# PIC32MZ2048EFM144 register map
Registers are 32-bit, access not given, reset 0x0 unless marked. A register's access mark holds for its fields unless they carry their own. Offsets are from the block's base; [hi:lo] are bit positions; {n}, {i} and the like mark numbered series; 'fields as' and 'values as' point back to an identical list.

## CAN2 — CAN2 peripheral
Base 0xBF881000
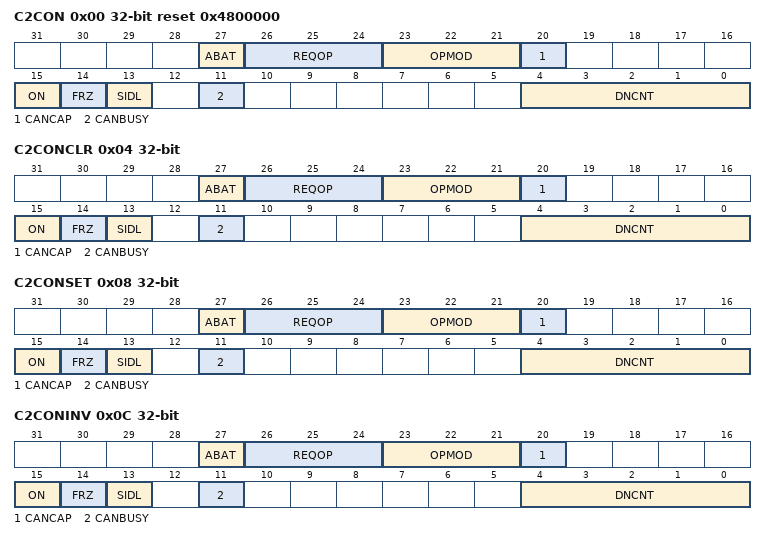
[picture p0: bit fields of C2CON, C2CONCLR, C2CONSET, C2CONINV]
0x00 C2CON reset 0x4800000
  [27] ABAT, [26:24] REQOP, [23:21] OPMOD, [20] CANCAP, [15] ON, [14] FRZ, [13] SIDL, [11] CANBUSY, [4:0] DNCNT
0x04 C2CONCLR
  fields as C2CON
0x08 C2CONSET
  fields as C2CON
0x0C C2CONINV
  fields as C2CON
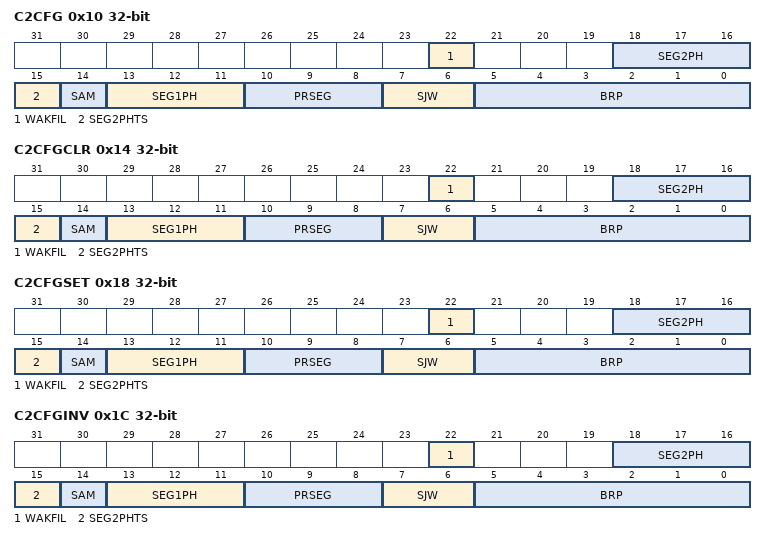
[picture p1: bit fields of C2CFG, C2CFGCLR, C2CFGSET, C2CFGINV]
0x10 C2CFG
  [22] WAKFIL, [18:16] SEG2PH, [15] SEG2PHTS, [14] SAM, [13:11] SEG1PH, [10:8] PRSEG, [7:6] SJW, [5:0] BRP
0x14 C2CFGCLR
  fields as C2CFG
0x18 C2CFGSET
  fields as C2CFG
0x1C C2CFGINV
  fields as C2CFG
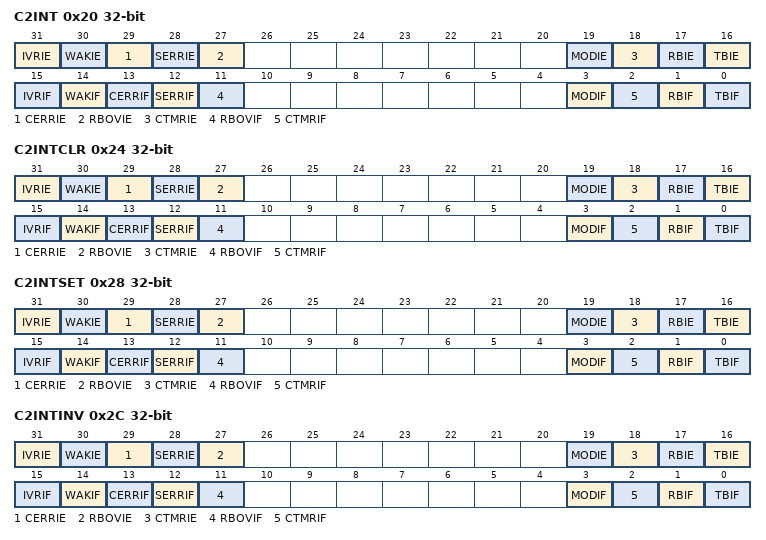
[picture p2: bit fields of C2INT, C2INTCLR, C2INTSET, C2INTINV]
0x20 C2INT
  [31] IVRIE, [30] WAKIE, [29] CERRIE, [28] SERRIE, [27] RBOVIE, [19] MODIE, [18] CTMRIE, [17] RBIE, [16] TBIE, [15] IVRIF, [14] WAKIF, [13] CERRIF, [12] SERRIF, [11] RBOVIF, [3] MODIF, [2] CTMRIF, [1] RBIF, [0] TBIF
0x24 C2INTCLR
  fields as C2INT
0x28 C2INTSET
  fields as C2INT
0x2C C2INTINV
  fields as C2INT
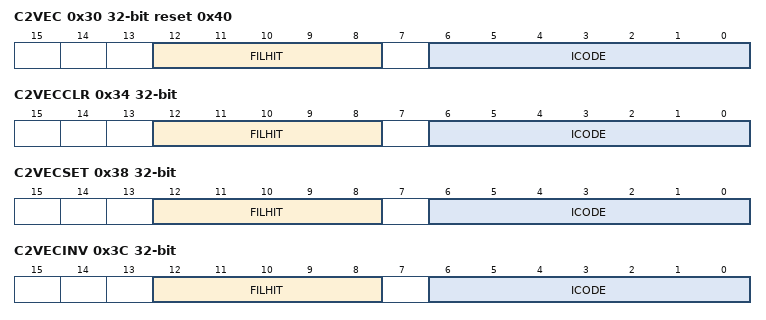
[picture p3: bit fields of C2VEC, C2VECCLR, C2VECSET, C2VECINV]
0x30 C2VEC reset 0x40
  [12:8] FILHIT, [6:0] ICODE
0x34 C2VECCLR
  [12:8] FILHIT, [6:0] ICODE
0x38 C2VECSET
  [12:8] FILHIT, [6:0] ICODE
0x3C C2VECINV
  [12:8] FILHIT, [6:0] ICODE
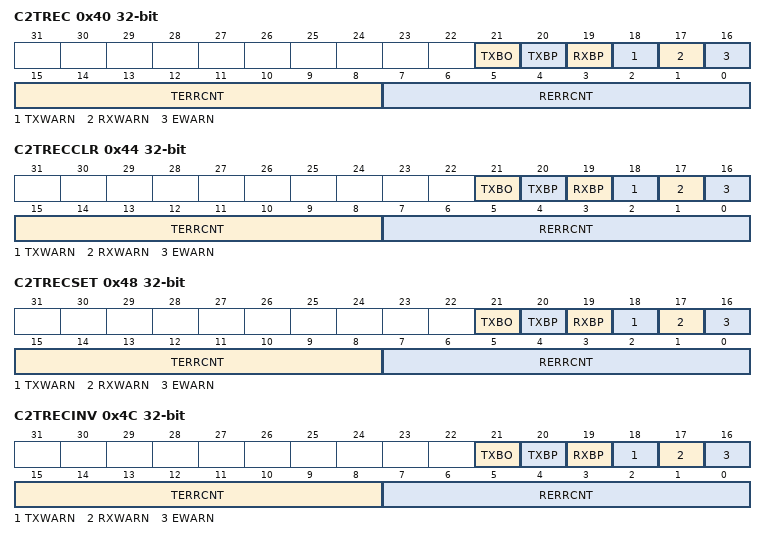
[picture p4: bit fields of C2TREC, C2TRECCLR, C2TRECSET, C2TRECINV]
0x40 C2TREC
  [21] TXBO, [20] TXBP, [19] RXBP, [18] TXWARN, [17] RXWARN, [16] EWARN, [15:8] TERRCNT, [7:0] RERRCNT
0x44 C2TRECCLR
  fields as C2TREC
0x48 C2TRECSET
  fields as C2TREC
0x4C C2TRECINV
  fields as C2TREC
0x50 C2FSTAT
  [31:0] FIFOIP
0x54 C2FSTATCLR
  [31:0] FIFOIP
0x58 C2FSTATSET
  [31:0] FIFOIP
0x5C C2FSTATINV
  [31:0] FIFOIP
0x60 C2RXOVF
  [31:0] RXOVF
0x64 C2RXOVFCLR
  [31:0] RXOVF
0x68 C2RXOVFSET
  [31:0] RXOVF
0x6C C2RXOVFINV
  [31:0] RXOVF
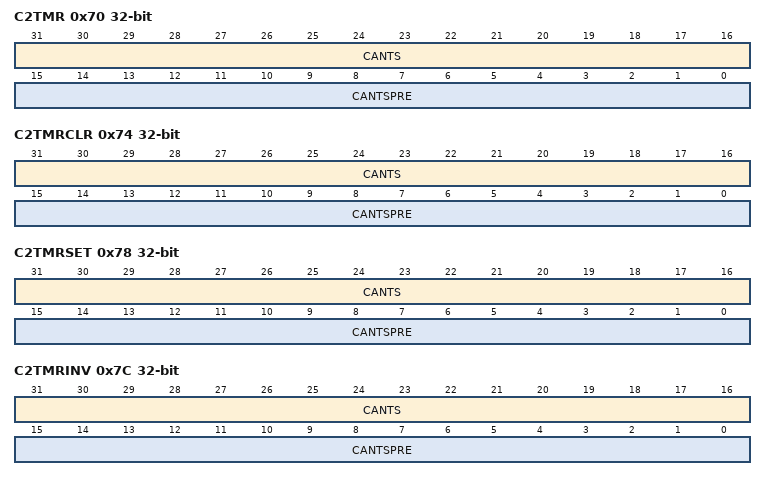
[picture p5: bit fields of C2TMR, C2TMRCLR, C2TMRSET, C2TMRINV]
0x70 C2TMR
  [31:16] CANTS, [15:0] CANTSPRE
0x74 C2TMRCLR
  [31:16] CANTS, [15:0] CANTSPRE
0x78 C2TMRSET
  [31:16] CANTS, [15:0] CANTSPRE
0x7C C2TMRINV
  [31:16] CANTS, [15:0] CANTSPRE
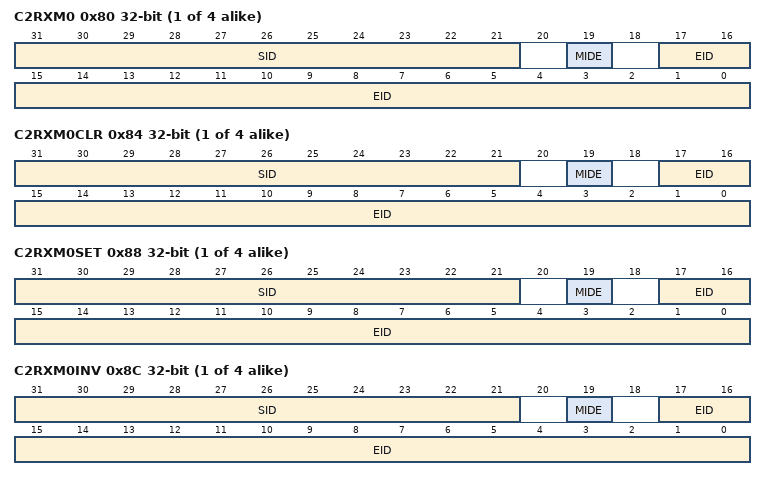
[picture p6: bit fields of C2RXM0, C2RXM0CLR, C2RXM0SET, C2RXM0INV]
{0x80+0x10*i} C2RXM{i} (i=0..3)
  [31:21] SID, [19] MIDE, [17:0] EID
{0x84+0x10*i} C2RXM{i}CLR (i=0..3)
  [31:21] SID, [19] MIDE, [17:0] EID
{0x88+0x10*i} C2RXM{i}SET (i=0..3)
  [31:21] SID, [19] MIDE, [17:0] EID
{0x8C+0x10*i} C2RXM{i}INV (i=0..3)
  [31:21] SID, [19] MIDE, [17:0] EID
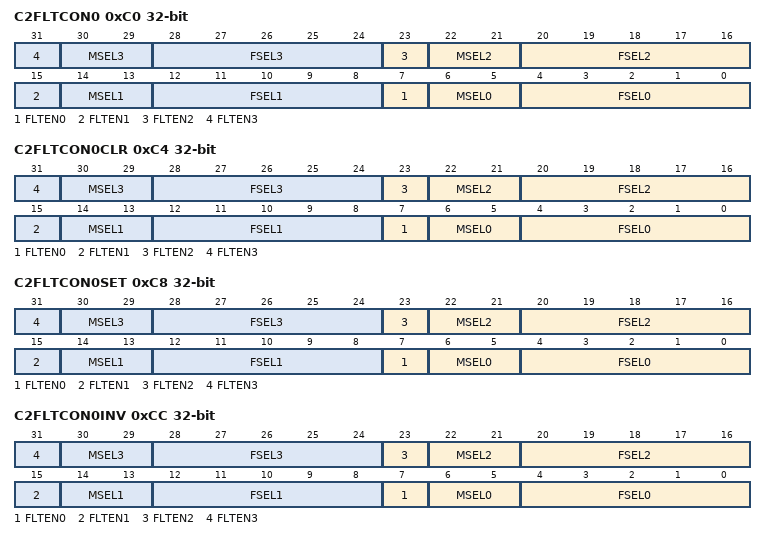
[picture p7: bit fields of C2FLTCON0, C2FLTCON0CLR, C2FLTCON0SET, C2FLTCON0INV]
0xC0 C2FLTCON0
  [8n+7] FLTEN{n} (n=0..3), [8n+6:8n+5] MSEL{n} (n=0..3), [8n+4:8n] FSEL{n} (n=0..3)
0xC4 C2FLTCON0CLR
  fields as C2FLTCON0
0xC8 C2FLTCON0SET
  fields as C2FLTCON0
0xCC C2FLTCON0INV
  fields as C2FLTCON0
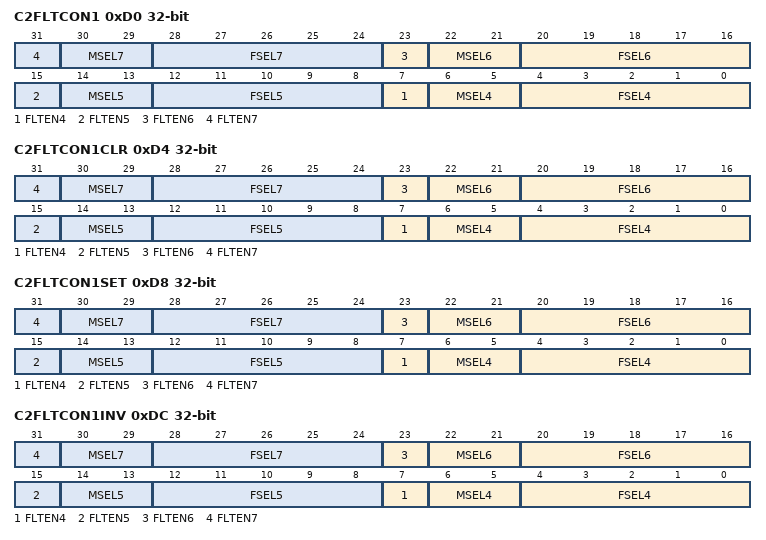
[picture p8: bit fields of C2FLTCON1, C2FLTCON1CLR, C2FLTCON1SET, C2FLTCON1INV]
0xD0 C2FLTCON1
  [8n-25] FLTEN{n} (n=4..7), [8n-26:8n-27] MSEL{n} (n=4..7), [8n-28:8n-32] FSEL{n} (n=4..7)
0xD4 C2FLTCON1CLR
  fields as C2FLTCON1
0xD8 C2FLTCON1SET
  fields as C2FLTCON1
0xDC C2FLTCON1INV
  fields as C2FLTCON1
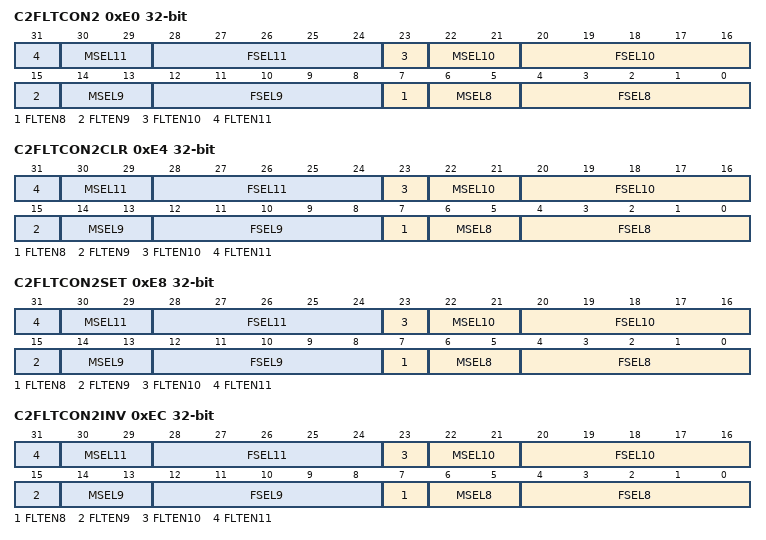
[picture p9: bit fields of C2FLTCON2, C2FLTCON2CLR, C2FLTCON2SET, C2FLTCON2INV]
0xE0 C2FLTCON2
  [8n-57] FLTEN{n} (n=8..11), [8n-58:8n-59] MSEL{n} (n=8..11), [8n-60:8n-64] FSEL{n} (n=8..11)
0xE4 C2FLTCON2CLR
  fields as C2FLTCON2
0xE8 C2FLTCON2SET
  fields as C2FLTCON2
0xEC C2FLTCON2INV
  fields as C2FLTCON2
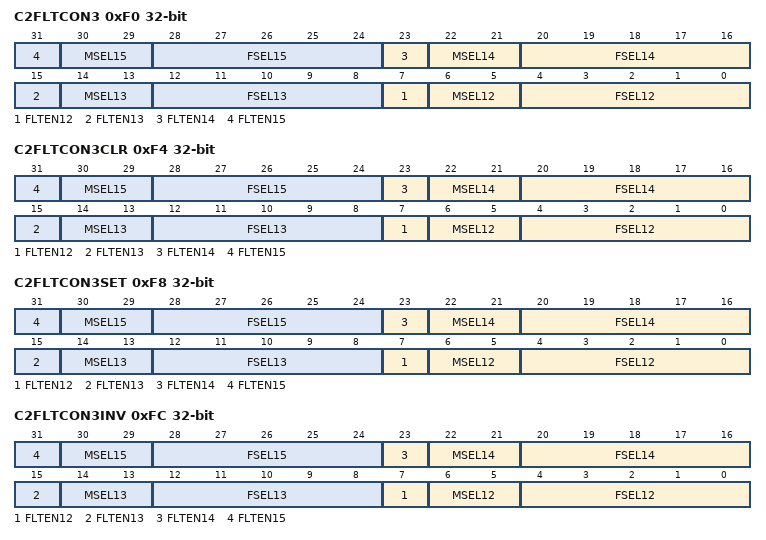
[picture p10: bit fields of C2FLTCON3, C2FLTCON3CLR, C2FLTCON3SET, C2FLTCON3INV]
0xF0 C2FLTCON3
  [8n-89] FLTEN{n} (n=12..15), [8n-90:8n-91] MSEL{n} (n=12..15), [8n-92:8n-96] FSEL{n} (n=12..15)
0xF4 C2FLTCON3CLR
  fields as C2FLTCON3
0xF8 C2FLTCON3SET
  fields as C2FLTCON3
0xFC C2FLTCON3INV
  fields as C2FLTCON3
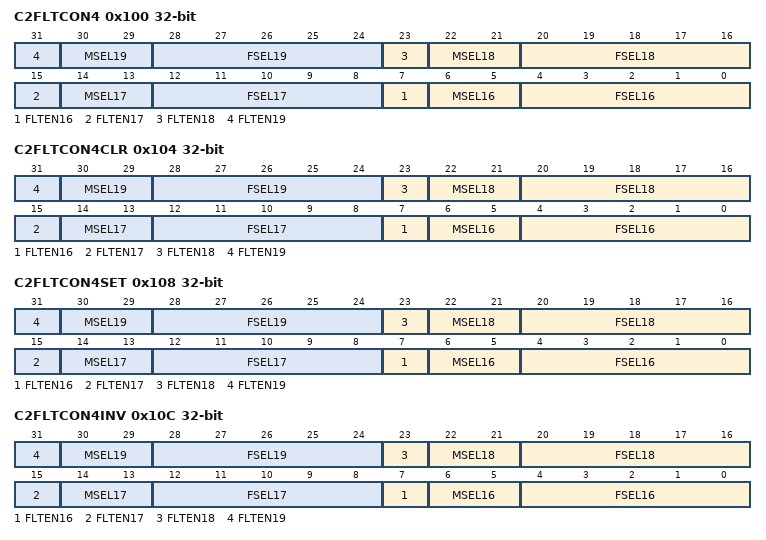
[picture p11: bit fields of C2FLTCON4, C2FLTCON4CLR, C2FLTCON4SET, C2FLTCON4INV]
0x100 C2FLTCON4
  [8n-121] FLTEN{n} (n=16..19), [8n-122:8n-123] MSEL{n} (n=16..19), [8n-124:8n-128] FSEL{n} (n=16..19)
0x104 C2FLTCON4CLR
  fields as C2FLTCON4
0x108 C2FLTCON4SET
  fields as C2FLTCON4
0x10C C2FLTCON4INV
  fields as C2FLTCON4
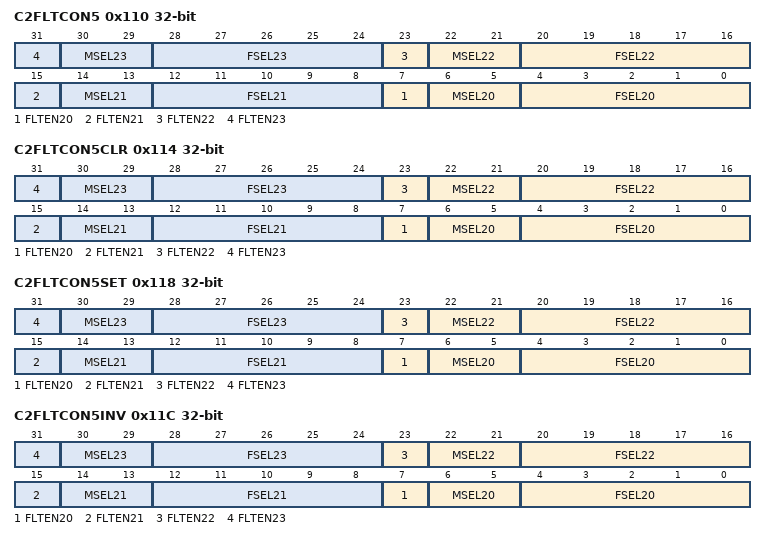
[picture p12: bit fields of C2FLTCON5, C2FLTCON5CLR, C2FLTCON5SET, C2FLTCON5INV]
0x110 C2FLTCON5
  [8n-153] FLTEN{n} (n=20..23), [8n-154:8n-155] MSEL{n} (n=20..23), [8n-156:8n-160] FSEL{n} (n=20..23)
0x114 C2FLTCON5CLR
  fields as C2FLTCON5
0x118 C2FLTCON5SET
  fields as C2FLTCON5
0x11C C2FLTCON5INV
  fields as C2FLTCON5
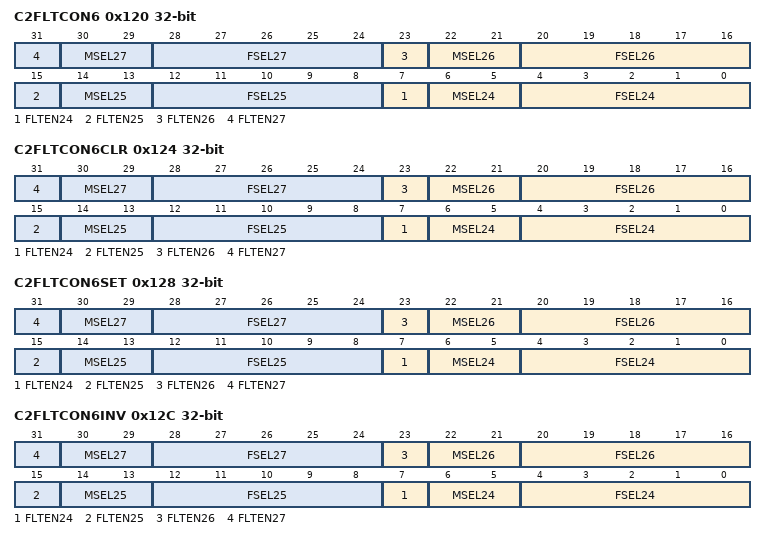
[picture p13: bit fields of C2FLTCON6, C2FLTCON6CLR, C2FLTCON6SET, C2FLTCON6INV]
0x120 C2FLTCON6
  [8n-185] FLTEN{n} (n=24..27), [8n-186:8n-187] MSEL{n} (n=24..27), [8n-188:8n-192] FSEL{n} (n=24..27)
0x124 C2FLTCON6CLR
  fields as C2FLTCON6
0x128 C2FLTCON6SET
  fields as C2FLTCON6
0x12C C2FLTCON6INV
  fields as C2FLTCON6
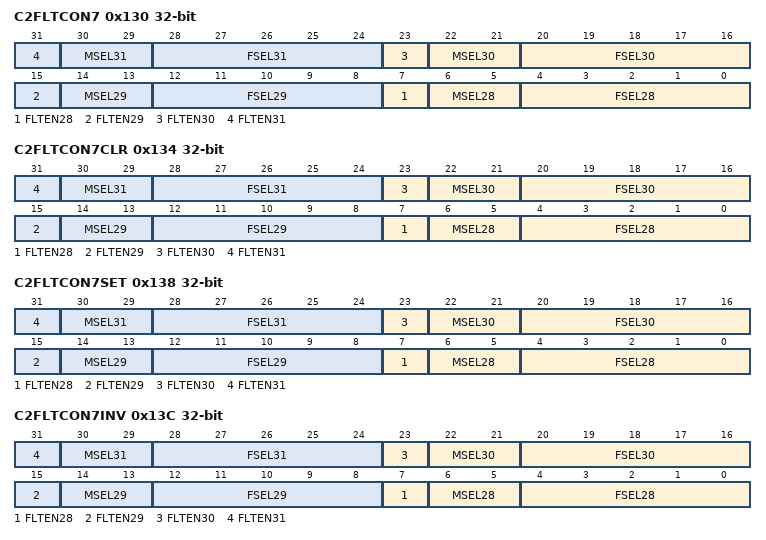
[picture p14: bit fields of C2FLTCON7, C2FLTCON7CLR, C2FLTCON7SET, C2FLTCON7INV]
0x130 C2FLTCON7
  [8n-217] FLTEN{n} (n=28..31), [8n-218:8n-219] MSEL{n} (n=28..31), [8n-220:8n-224] FSEL{n} (n=28..31)
0x134 C2FLTCON7CLR
  fields as C2FLTCON7
0x138 C2FLTCON7SET
  fields as C2FLTCON7
0x13C C2FLTCON7INV
  fields as C2FLTCON7
{0x140+0x10*i} C2RXF{i} (i=0..31)
  [31:21] SID, [19] EXID, [17:0] EID
{0x144+0x10*i} C2RXF{i}CLR (i=0..31)
  [31:21] SID, [19] EXID, [17:0] EID
{0x148+0x10*i} C2RXF{i}SET (i=0..31)
  [31:21] SID, [19] EXID, [17:0] EID
{0x14C+0x10*i} C2RXF{i}INV (i=0..31)
  [31:21] SID, [19] EXID, [17:0] EID
0x340 C2FIFOBA
  [31:2] FIFOBA
0x344 C2FIFOBACLR
  [31:2] FIFOBA
0x348 C2FIFOBASET
  [31:2] FIFOBA
0x34C C2FIFOBAINV
  [31:2] FIFOBA
{0x350+0x40*i} C2FIFOCON{i} (i=0..31)
  [20:16] FSIZE, [14] FRESET, [13] UINC, [12] DONLY, [7] TXEN, [6] TXABAT, [5] TXLARB, [4] TXERR, [3] TXREQ, [2] RTREN, [1:0] TXPRI
{0x354+0x40*i} C2FIFOCON{i}CLR (i=0..31)
  fields as C2FIFOCON0
{0x358+0x40*i} C2FIFOCON{i}SET (i=0..31)
  fields as C2FIFOCON0
{0x35C+0x40*i} C2FIFOCON{i}INV (i=0..31)
  fields as C2FIFOCON0
{0x360+0x40*i} C2FIFOINT{i} (i=0..31)
  [26] TXNFULLIE, [25] TXHALFIE, [24] TXEMPTYIE, [19] RXOVFLIE, [18] RXFULLIE, [17] RXHALFIE, [16] RXNEMPTYIE, [10] TXNFULLIF, [9] TXHALFIF, [8] TXEMPTYIF, [3] RXOVFLIF, [2] RXFULLIF, [1] RXHALFIF, [0] RXNEMPTYIF
{0x364+0x40*i} C2FIFOINT{i}CLR (i=0..31)
  fields as C2FIFOINT0
{0x368+0x40*i} C2FIFOINT{i}SET (i=0..31)
  fields as C2FIFOINT0
{0x36C+0x40*i} C2FIFOINT{i}INV (i=0..31)
  fields as C2FIFOINT0
{0x370+0x40*i} C2FIFOUA{i} (i=0..31)
  [31:2] FIFOUA
{0x374+0x40*i} C2FIFOUA{i}CLR (i=0..31)
  [31:2] FIFOUA
{0x378+0x40*i} C2FIFOUA{i}SET (i=0..31)
  [31:2] FIFOUA
{0x37C+0x40*i} C2FIFOUA{i}INV (i=0..31)
  [31:2] FIFOUA
{0x380+0x40*i} C2FIFOCI{i} (i=0..31)
  [4:0] CFIFOCI
{0x384+0x40*i} C2FIFOCI{i}CLR (i=0..31)
  [4:0] CFIFOCI
{0x388+0x40*i} C2FIFOCI{i}SET (i=0..31)
  [4:0] CFIFOCI
{0x38C+0x40*i} C2FIFOCI{i}INV (i=0..31)
  [4:0] CFIFOCI
